# CH32H417 register map
Vendor: WCH Ltd.; File version: 1.2
Registers are 32-bit, read-write, reset 0x0 unless marked. A register's access mark holds for its fields unless they carry their own. Offsets are from the block's base; [hi:lo] are bit positions; {n}, {i} and the like mark numbered series.

## DVP — Digital Video Port
Base 0x40025800
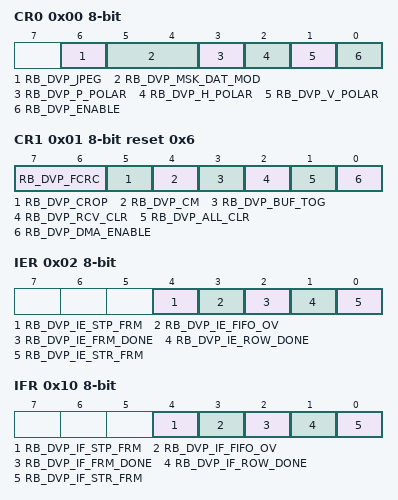
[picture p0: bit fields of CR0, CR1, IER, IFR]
0x00 CR0 8-bit — Digital Video control register (DVP_CR0)
  [6] RB_DVP_JPEG — DVP JPEG mode
  [5:4] RB_DVP_MSK_DAT_MOD — DVP data mode
  [3] RB_DVP_P_POLAR — DVP PCLK polarity control
  [2] RB_DVP_H_POLAR — DVP HSYNC polarity control
  [1] RB_DVP_V_POLAR — DVP VSYNC polarity control
  [0] RB_DVP_ENABLE — DVP enable
0x01 CR1 8-bit reset 0x6 — Digital Video control register (DVP_CR1)
  [7:6] RB_DVP_FCRC — DVP frame capture rate control
  [5] RB_DVP_CROP — DVP Crop feature enable
  [4] RB_DVP_CM — DVP capture mode
  [3] RB_DVP_BUF_TOG — DVP bug toggle by software
  [2] RB_DVP_RCV_CLR — DVP receive logic clear
  [1] RB_DVP_ALL_CLR — DVP all clear
  [0] RB_DVP_DMA_ENABLE — DVP dma enable
0x02 IER 8-bit — Digital Video Interrupt register (DVP_IER)
  [4] RB_DVP_IE_STP_FRM — DVP frame stop interrupt enable
  [3] RB_DVP_IE_FIFO_OV — DVP receive fifo overflow interrupt enable
  [2] RB_DVP_IE_FRM_DONE — DVP frame received done interrupt enable
  [1] RB_DVP_IE_ROW_DONE — DVP row received done interrupt enable
  [0] RB_DVP_IE_STR_FRM — DVP frame start interrupt enable
0x04 ROW_NUM 16-bit — Image line count configuration register (DVP_ROW_NUM)
  [15:0] RB_DVP_ROW_NUM — The number of rows of frame image data
0x06 COL_NUM 16-bit — Image column number configuration register (DVP_COL_NUM)
  [15:0] RB_DVP_COL_NUM — Number of PCLK cycles for row data
0x08 DMA_BUF0 — Digital Video DMA address register (DVP_DMA_BUF0)
  [31:0] RB_DVP_DMA_BUF0 — DMA receive address 0
0x0C DMA_BUF1 — Digital Video DMA address register (DVP_DMA_BUF1)
  [31:0] RB_DVP_DMA_BUF1 — DMA receive address 1
0x10 IFR 8-bit — Digital Video Flag register (DVP_IFR)
  [4] RB_DVP_IF_STP_FRM — DVP frame stop interrupt enable
  [3] RB_DVP_IF_FIFO_OV — DVP receive fifo overflow interrupt enable
  [2] RB_DVP_IF_FRM_DONE — DVP frame received done interrupt enable
  [1] RB_DVP_IF_ROW_DONE — DVP row received done interrupt enable
  [0] RB_DVP_IF_STR_FRM — DVP frame start interrupt enable
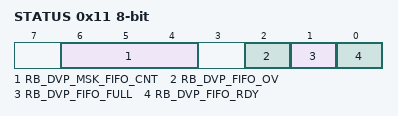
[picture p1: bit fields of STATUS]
0x11 STATUS 8-bit ro — Digital Video STATUS register (DVP_STATUS)
  [6:4] RB_DVP_MSK_FIFO_CNT — DVP receive fifo overflow interrupt enable
  [2] RB_DVP_FIFO_OV — DVP frame received done interrupt enable
  [1] RB_DVP_FIFO_FULL — DVP row received done interrupt enable
  [0] RB_DVP_FIFO_RDY — DVP frame start interrupt enable
0x14 ROW_CNT 16-bit ro — Digital Video line counter register (DVP_ROW_CNT)
  [15:0] RB_DVP_ROW_CNT — The number of rows of frame image data
0x18 HOFFCNT 16-bit — Digital Video horizontal displacement register (DVP_HOFFCNT)
  [15:0] RB_DVP_HOFFCNT — Number of PCLK cycles for row data
0x1A VST 16-bit — Digital Video line number register (DVP_VST)
  [15:0] RB_DVP_VST — The number of lines captured by the image
0x1C CAPCNT 16-bit — Digital Video Capture count register (DVP_CAPCNT)
  [15:0] RB_DVP_CAPCNT — Number of PCLK cycles captured by clipping window
0x1E VLINE 16-bit — Digital Video Vertical line count register (DVP_VLINE)
  [15:0] RB_DVP_VLINE — Crop the number of rows captured by window
0x20 DR ro — Digital Video Data register (DVP_DR)
  [31:0] RB_DVP_DR — Prevent DMA overflow

## RNG — Random number generator
Base 0x40023C00
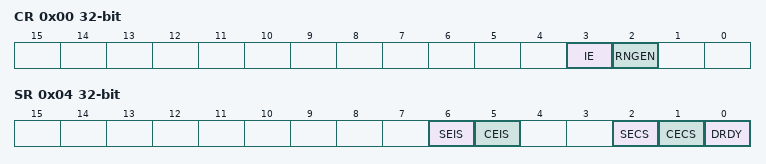
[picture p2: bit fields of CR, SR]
0x00 CR — control register
  [3] IE — Interrupt enable
  [2] RNGEN — Random number generator enable
0x04 SR access per field — status register
  [6] SEIS rw — Seed error interrupt status
  [5] CEIS rw — Clock error interrupt status
  [2] SECS ro — Seed error current status
  [1] CECS ro — Clock error current status
  [0] DRDY ro — Data ready
0x08 DR ro — data register
  [31:0] RNDATA — Random data

## PIOC — Programmable protocol I/O microcontroller
Base 0x40025C00
0x00 SFR_INDIR_PORT 8-bit access not given — Indirectly addressed data read/write ports
0x01 RSFR_INDIR_PORT2 8-bit access not given — Indirectly addresses the data read/write port of 2
0x02 SFR_PRG_COUNT 8-bit access not given — Program counters for the low bytes of the PC
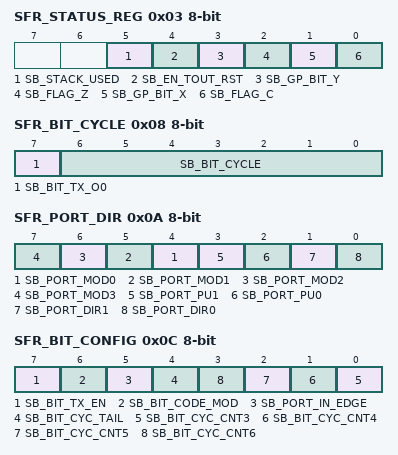
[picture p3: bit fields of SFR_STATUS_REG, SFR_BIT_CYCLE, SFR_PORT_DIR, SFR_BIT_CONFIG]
0x03 SFR_STATUS_REG 8-bit access not given — Status registers
  [5] SB_STACK_USED — Current stack usage flags
  [4] SB_EN_TOUT_RST — Timer Timeout Reset Enabled
  [3] SB_GP_BIT_Y — a generic bit variable Y, defined and used by the application
  [2] SB_FLAG_Z — ALU zero flag, whether the result is 00H
  [1] SB_GP_BIT_X — A generic bit variable X, defined and used by the application
  [0] SB_FLAG_C — ALU carry flag, whether the result is carried or produced by displacement
0x04 SFR_INDIR_ADDR 8-bit ro — Indirectly addressed address registers
0x05 SFR_TMR0_COUNT 8-bit ro — The counter register of timer 0
0x06 SFR_TIMER_CTRL 8-bit ro — The control register of the timer
0x07 SFR_TMR0_INIT 8-bit ro — The initial register of timer 0
0x08 SFR_BIT_CYCLE 8-bit — Periodic registers for coded bits
  [7] SB_BIT_TX_O0 — The raw bit data of the encoded bit to be sent, which is a double-buffered structure
  [6:0] SB_BIT_CYCLE — Sets the width of the encoded bits in clock cycles, which is the actual number of bits minus 1
0x09 SFR_INDIR_ADDR2 8-bit ro — Address registers for indirect address 2
0x0A SFR_PORT_DIR 8-bit ro — The port direction sets the register
  [n+4] SB_PORT_MOD{n} (n=0..3) — Pin mode control, host side defines the purpose
  [3] SB_PORT_PU1 — IO1 Pin Pull-Up Enables
  [2] SB_PORT_PU0 — IO0 Pin Pull-Up Enables
  [1] SB_PORT_DIR1 — IO1 Pin Direction Control
  [0] SB_PORT_DIR0 — IO0 Pin Direction Control
0x0B SFR_PORT_IO 8-bit ro — Port input and output registers
0x0C SFR_BIT_CONFIG 8-bit ro — Coded bit configuration registers
  [7] SB_BIT_TX_EN — The transmission of the coded bits is enabled
  [6] SB_BIT_CODE_MOD — How the coded bits are modulated
  [5] SB_PORT_IN_EDGE — Pin input level sampling point selection
  [4] SB_BIT_CYC_TAIL — Periodic state of the encoded bits
  [n-3] SB_BIT_CYC_CNT{n} (n=3..6) — The periodic timing state of the encoded bits
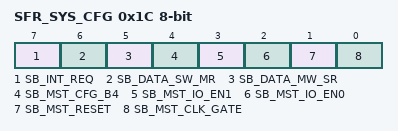
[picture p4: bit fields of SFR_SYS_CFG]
0x1C SFR_SYS_CFG 8-bit access per field — System configuration registers
  [7] SB_INT_REQ ro — Interrupt Request Activation Bits
  [6] SB_DATA_SW_MR ro — SFR_CTRL_RD wait to read the status bit
  [5] SB_DATA_MW_SR ro — SFR_CTRL_WR waiting to read the status bit
  [4] SB_MST_CFG_B4 wo — Configure information bits, software-defined uses
  [3] SB_MST_IO_EN1 wo — Mode and output control switches for IO1 pins
  [2] SB_MST_IO_EN0 wo — Mode and output control switches for IO0 pins
  [1] SB_MST_RESET wo — Force eMCU Reset
  [0] SB_MST_CLK_GATE wo — Global Clock Control for eMCUs
0x1D SFR_CTRL_RD 8-bit ro — The eMCU reads and writes and the host reads only the registers
0x1E SFR_CTRL_WR 8-bit — The host reads and writes and the eMCU reads only registers
0x1F SFR_DATA_EXCH 8-bit — Data exchange registers
{0x20+i} SFR_DATA_REG{i} 8-bit (i=0..31) — Data register {i}
